# STM32U5A5 register map
File version: 1.0
CPU: CM33 r0p1, little endian, MPU, FPU, 4 interrupt priority bits
Registers are 32-bit, read-write, reset 0x0 unless marked. A register's access mark holds for its fields unless they carry their own. Offsets are from the block's base; [hi:lo] are bit positions; {n}, {i} and the like mark numbered series; 'fields as' and 'values as' point back to an identical list.

## RAMCFG
Base 0x40026000
Same registers: SEC_RAMCFG 0x50026000
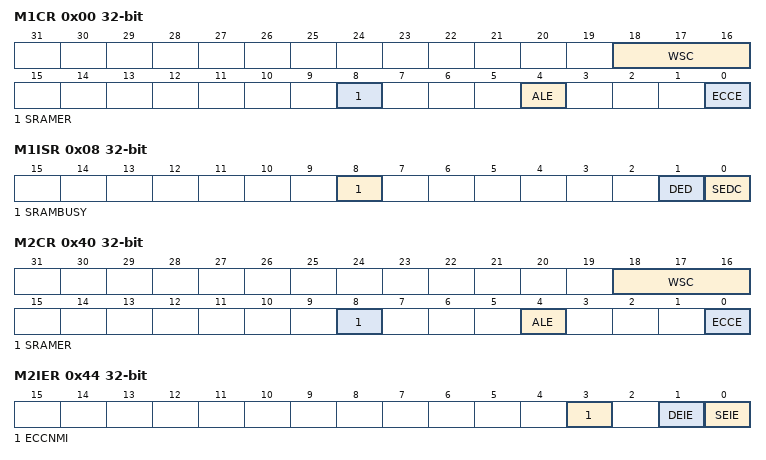
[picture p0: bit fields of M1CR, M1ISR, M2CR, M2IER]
0x00 M1CR — RAMCFG SRAM x control register
  [18:16] WSC, [8] SRAMER, [4] ALE, [0] ECCE
0x08 M1ISR ro — RAMCFG RAMx interrupt status register
  [8] SRAMBUSY, [1] DED, [0] SEDC
0x28 RAM1ERKEYR wo — RAMCFG SRAM x erase key register
  [7:0] ERASEKEY
0x40 M2CR — RAMCFG SRAM x control register
  [18:16] WSC, [8] SRAMER, [4] ALE, [0] ECCE
0x44 M2IER — RAMCFG SRAM x interrupt enable register
  [3] ECCNMI, [1] DEIE, [0] SEIE
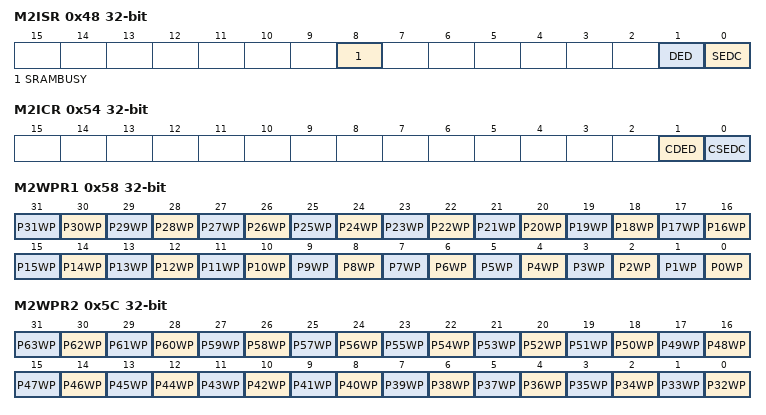
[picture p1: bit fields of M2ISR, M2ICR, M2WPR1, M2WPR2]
0x48 M2ISR ro — RAMCFG RAMx interrupt status register
  [8] SRAMBUSY, [1] DED, [0] SEDC
0x4C M2SEAR ro — RAMCFG RAM x ECC single error address register
  [31:0] ESEA
0x50 M2DEAR ro — RAMCFG RAM x ECC double error address register
  [31:0] EDEA
0x54 M2ICR — RAMCFG RAM x interrupt clear register x
  [1] CDED, [0] CSEDC
0x58 M2WPR1 — RAMCFG SRAM2 write protection register 1
  [n] P{n}WP (n=0..31)
0x5C M2WPR2 — RAMCFG SRAM2 write protection register 2
  [n-32] P{n}WP (n=32..63)
0x64 M2ECCKEYR wo — RAMCFG SRAM x ECC key register
  [7:0] ECCKEY
0x68 M2ERKEYR wo — RAMCFG SRAM x erase key register
  [7:0] ERASEKEY
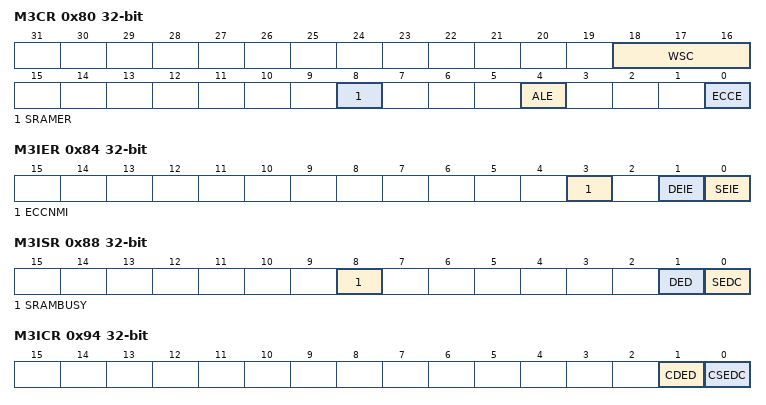
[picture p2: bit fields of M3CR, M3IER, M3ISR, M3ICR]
0x80 M3CR — RAMCFG SRAM x control register
  [18:16] WSC, [8] SRAMER, [4] ALE, [0] ECCE
0x84 M3IER — RAMCFG SRAM x interrupt enable register
  [3] ECCNMI, [1] DEIE, [0] SEIE
0x88 M3ISR ro — RAMCFG RAMx interrupt status register
  [8] SRAMBUSY, [1] DED, [0] SEDC
0x8C M3SEAR ro — RAMCFG RAM x ECC single error address register
  [31:0] ESEA
0x90 M3DEAR ro — RAMCFG RAM x ECC double error address register
  [31:0] EDEA
0x94 M3ICR — RAMCFG RAM x interrupt clear register x
  [1] CDED, [0] CSEDC
0xA4 M3ECCKEYR wo — RAMCFG SRAM x ECC key register
  [7:0] ECCKEY
0xA8 M3ERKEYR wo — RAMCFG SRAM x erase key register
  [7:0] ERASEKEY
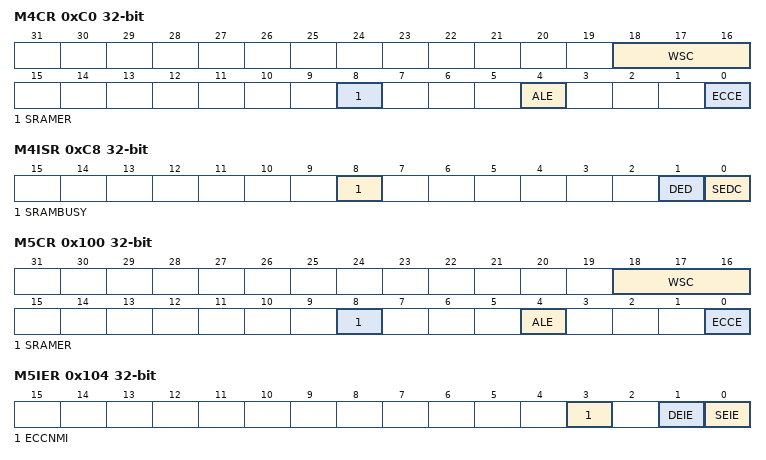
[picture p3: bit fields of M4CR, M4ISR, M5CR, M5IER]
0xC0 M4CR — RAMCFG SRAM x control register
  [18:16] WSC, [8] SRAMER, [4] ALE, [0] ECCE
0xC8 M4ISR ro — RAMCFG RAMx interrupt status register
  [8] SRAMBUSY, [1] DED, [0] SEDC
0xE8 M4ERKEYR wo — RAMCFG SRAM x erase key register
  [7:0] ERASEKEY
0x100 M5CR — RAMCFG SRAM x control register
  [18:16] WSC, [8] SRAMER, [4] ALE, [0] ECCE
0x104 M5IER — RAMCFG SRAM x interrupt enable register
  [3] ECCNMI, [1] DEIE, [0] SEIE
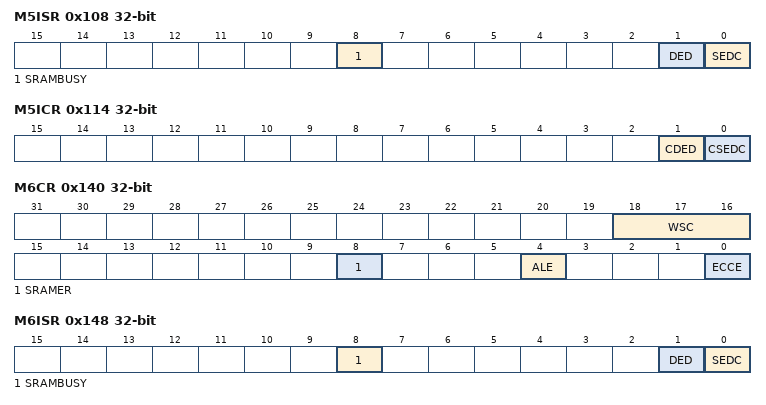
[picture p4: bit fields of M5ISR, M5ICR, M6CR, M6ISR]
0x108 M5ISR ro — RAMCFG RAMx interrupt status register
  [8] SRAMBUSY, [1] DED, [0] SEDC
0x10C M5SEAR ro — RAMCFG RAM x ECC single error address register
  [31:0] ESEA
0x110 M5DEAR ro — RAMCFG RAM x ECC double error address register
  [31:0] EDEA
0x114 M5ICR — RAMCFG RAM x interrupt clear register x
  [1] CDED, [0] CSEDC
0x124 M5ECCKEYR — RAMCFG RAM x interrupt clear register x
  [7:0] ECCKEY
0x128 M5ERKEYR
  [7:0] ERASEKEY wo — Erase write protection key The following steps are required to unlock the write protection of the SRAMER bit in the RAMCFG_MxCR register. 1) Write 0xCA into ERASEKEY[7:0]. 2) Write 0x53 into ERASEKEY[7:0]. Note: Writing a wrong key reactivates the write protection.
0x140 M6CR — memory x control register
  [18:16] WSC, [8] SRAMER, [4] ALE, [0] ECCE
0x148 M6ISR ro
  [8] SRAMBUSY — SRAM busy with erase operation Note: Depending on the SRAM, the erase operation can be performed due to software request, system reset if the option bit is enabled, tamper detection or readout protection regression. Refer to .
  [1] DED — ECC double error detected Note: This bit is reserved and must be kept at reset value in SRAM1, SRAM4 and SRAM5 interrupt status registers.
  [0] SEDC — ECC single error detected and corrected Note: This bit is reserved and must be kept at reset value in SRAM1, SRAM4 and SRAM5 interrupt status registers.
0x168 M6ERKEYR
  fields as M5ERKEYR

## SYSCFG — System configuration controller
Base 0x46000400
Same registers: SEC_SYSCFG 0x56000400
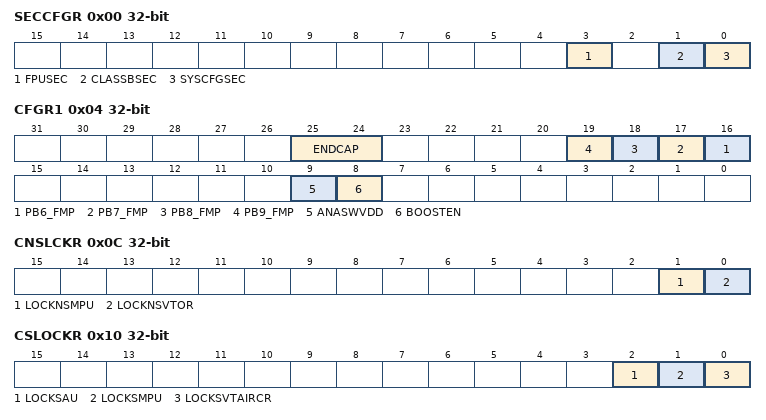
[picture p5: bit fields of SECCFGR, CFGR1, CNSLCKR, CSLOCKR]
0x00 SECCFGR — SYSCFG secure configuration register
  [3] FPUSEC
  [1] CLASSBSEC
  [0] SYSCFGSEC — SYSCFG clock control security
0x04 CFGR1 — configuration register 1
  [25:24] ENDCAP
  [n+10] PB{n}_FMP (n=6..9)
  [9] ANASWVDD — GPIO analog switch control voltage selection
  [8] BOOSTEN — I/O analog switch voltage booster enable
0x08 FPUIMR reset 0x1F — FPU interrupt mask register
  [5:0] FPU_IE — Floating point unit interrupts enable bits
0x0C CNSLCKR — SYSCFG CPU non-secure lock register
  [1] LOCKNSMPU — Non-secure MPU registers lock
  [0] LOCKNSVTOR — VTOR_NS register lock
0x10 CSLOCKR — SYSCFG CPU secure lock register
  [2] LOCKSAU, [1] LOCKSMPU, [0] LOCKSVTAIRCR
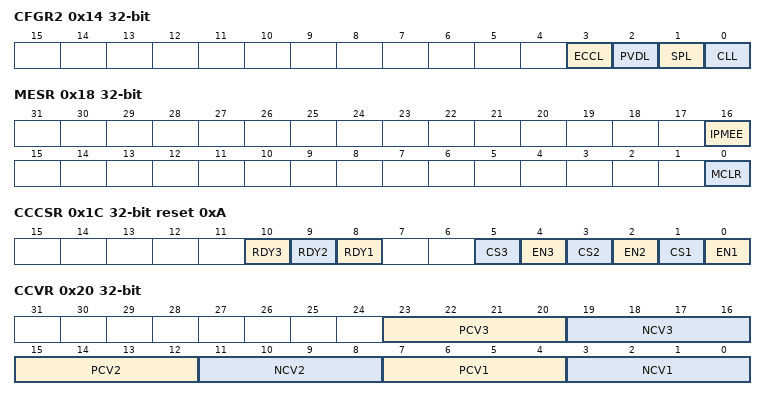
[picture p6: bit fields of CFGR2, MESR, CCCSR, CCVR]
0x14 CFGR2 — configuration register 2
  [3] ECCL — ECC Lock
  [2] PVDL — PVD lock enable bit
  [1] SPL — SRAM ECC lock bit
  [0] CLL — LOCKUP (hardfault) output enable bit
0x18 MESR — memory erase status register
  [16] IPMEE, [0] MCLR
0x1C CCCSR access per field reset 0xA — compensation cell control/status register
  [10] RDY3 ro, [9] RDY2 ro, [8] RDY1 ro, [5] CS3 rw, [4] EN3 rw, [3] CS2 rw, [2] EN2 rw, [1] CS1 rw, [0] EN1 rw
0x20 CCVR ro — compensation cell value register
  [23:20] PCV3, [19:16] NCV3, [15:12] PCV2, [11:8] NCV2, [7:4] PCV1, [3:0] NCV1
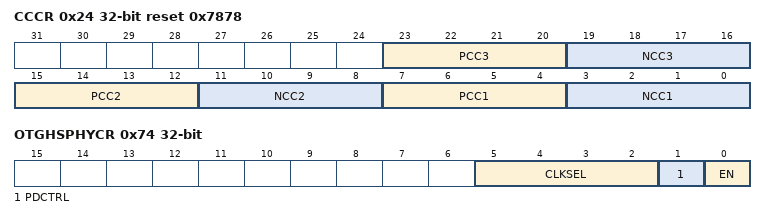
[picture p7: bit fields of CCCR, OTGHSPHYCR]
0x24 CCCR reset 0x7878 — compensation cell code register
  [23:20] PCC3, [19:16] NCC3, [15:12] PCC2, [11:8] NCC2, [7:4] PCC1, [3:0] NCC1
0x2C RSSCMDR — RSS command register
  [15:0] RSSCMD — RSS commands
0x74 OTGHSPHYCR — SYSCFG USB OTG_HS PHY register
  [5:2] CLKSEL, [1] PDCTRL, [0] EN
